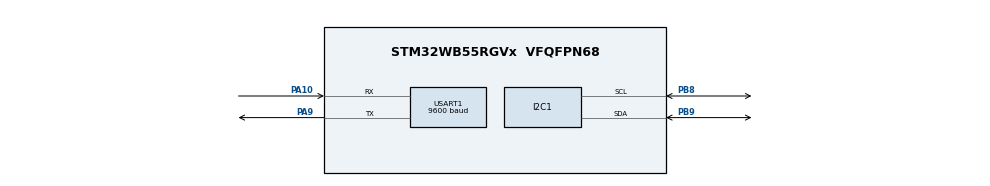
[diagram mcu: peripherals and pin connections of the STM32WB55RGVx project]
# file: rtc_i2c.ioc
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I2C1.Timing=0x00100D14
Mcu.Family=STM32WB
Mcu.Name=STM32WB55RGVx
Mcu.Package=VFQFPN68
NVIC.PriorityGroup=NVIC_PRIORITYGROUP_4
PA10.Mode=Asynchronous
PA10.Signal=USART1_RX
PA9.Mode=Asynchronous
PA9.Signal=USART1_TX
PB8.Mode=I2C
PB8.Signal=I2C1_SCL
PB9.Mode=I2C
PB9.Signal=I2C1_SDA
ProjectManager.HeapSize=0x200
ProjectManager.StackSize=0x400
ProjectManager.TargetToolchain=STM32CubeIDE
RCC.APB3Freq_Value=16000000
RCC.HSE_VALUE=8000000
RCC.HSI48_VALUE=48000000
RCC.HSI_VALUE=16000000
RCC.LSE_VALUE=32768
RCC.VCOOutputFreq_Value=32000000
USART1.BaudRate=9600
USART1.VirtualMode-Asynchronous=VM_ASYNC
VP_MEMORYMAP_VS_MEMORYMAP.Mode=CurAppReg
board=custom

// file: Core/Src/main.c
/* USER CODE BEGIN Header */
/**
  ******************************************************************************
  * @file           : main.c
  * @brief          : Main program body
  ******************************************************************************
  * @attention
  *
  * Copyright (c) 2025 STMicroelectronics.
  * All rights reserved.
  *
  * This software is licensed under terms that can be found in the LICENSE file
  * in the root directory of this software component.
  * If no LICENSE file comes with this software, it is provided AS-IS.
  *
  ******************************************************************************
  */
/* USER CODE END Header */
#include "main.h"
#include "RTC_MCP79410_I2C.h"

I2C_HandleTypeDef hi2c1;

UART_HandleTypeDef huart1;

/* USER CODE BEGIN PV */
char tempTimeArray[20];   // Format: HH MM SS
char tempDateArray[20];
/* USER CODE END PV */

void SystemClock_Config(void);
void PeriphCommonClock_Config(void);
static void MX_GPIO_Init(void);
static void MX_I2C1_Init(void);
static void MX_USART1_UART_Init(void);
void UART_Print(char *str);

/* USER CODE BEGIN 0 */
//void UART_Print(char *str)
//{
//    HAL_UART_Transmit(&huart1, (uint8_t *)str, strlen(str), HAL_MAX_DELAY);
//}
///* USER CODE END 0 */

int main(void)
{

  /* MCU Configuration--------------------------------------------------------*/

  /* Reset of all peripherals, Initializes the Flash interface and the Systick. */
  HAL_Init();

  /* Configure the system clock */
  SystemClock_Config();

  /* Configure the peripherals common clocks */
  PeriphCommonClock_Config();

  /* Initialize all configured peripherals */
  MX_GPIO_Init();
  MX_I2C1_Init();
  MX_USART1_UART_Init();
  InitRtc();

  /* Infinite loop */
  while (1)
  {

	   GetTimeToRtcHmsAscii(tempTimeArray);

	   HAL_UART_Transmit(&huart1, (uint8_t*) tempTimeArray, strlen( tempTimeArray), HAL_MAX_DELAY);
	   HAL_UART_Transmit(&huart1, (uint8_t*)"\r\n", 2, HAL_MAX_DELAY);

	   HAL_Delay(100);

	   GetDateToRtcHmsAscii(tempDateArray);

	   HAL_UART_Transmit(&huart1, (uint8_t*)tempDateArray, strlen(tempDateArray), HAL_MAX_DELAY);
	   HAL_UART_Transmit(&huart1, (uint8_t*)"\r\n", 2, HAL_MAX_DELAY);

	   HAL_Delay(100);

  }
}

void SystemClock_Config(void)
{
  RCC_OscInitTypeDef RCC_OscInitStruct = {0};
  RCC_ClkInitTypeDef RCC_ClkInitStruct = {0};

  /** Configure the main internal regulator output voltage
  */
  __HAL_PWR_VOLTAGESCALING_CONFIG(PWR_REGULATOR_VOLTAGE_SCALE1);

  /** Initializes the RCC Oscillators according to the specified parameters
  * in the RCC_OscInitTypeDef structure.
  */
  RCC_OscInitStruct.OscillatorType = RCC_OSCILLATORTYPE_HSI|RCC_OSCILLATORTYPE_MSI;
  RCC_OscInitStruct.HSIState = RCC_HSI_ON;
  RCC_OscInitStruct.MSIState = RCC_MSI_ON;
  RCC_OscInitStruct.HSICalibrationValue = RCC_HSICALIBRATION_DEFAULT;
  RCC_OscInitStruct.MSICalibrationValue = RCC_MSICALIBRATION_DEFAULT;
  RCC_OscInitStruct.MSIClockRange = RCC_MSIRANGE_6;
  RCC_OscInitStruct.PLL.PLLState = RCC_PLL_NONE;
  if (HAL_RCC_OscConfig(&RCC_OscInitStruct) != HAL_OK)
  {
    Error_Handler();
  }

  /** Configure the SYSCLKSource, HCLK, PCLK1 and PCLK2 clocks dividers
  */
  RCC_ClkInitStruct.ClockType = RCC_CLOCKTYPE_HCLK4|RCC_CLOCKTYPE_HCLK2
                              |RCC_CLOCKTYPE_HCLK|RCC_CLOCKTYPE_SYSCLK
                              |RCC_CLOCKTYPE_PCLK1|RCC_CLOCKTYPE_PCLK2;
  RCC_ClkInitStruct.SYSCLKSource = RCC_SYSCLKSOURCE_MSI;
  RCC_ClkInitStruct.AHBCLKDivider = RCC_SYSCLK_DIV1;
  RCC_ClkInitStruct.APB1CLKDivider = RCC_HCLK_DIV1;
  RCC_ClkInitStruct.APB2CLKDivider = RCC_HCLK_DIV1;
  RCC_ClkInitStruct.AHBCLK2Divider = RCC_SYSCLK_DIV1;
  RCC_ClkInitStruct.AHBCLK4Divider = RCC_SYSCLK_DIV1;

  if (HAL_RCC_ClockConfig(&RCC_ClkInitStruct, FLASH_LATENCY_0) != HAL_OK)
  {
    Error_Handler();
  }
}

void PeriphCommonClock_Config(void)
{
  RCC_PeriphCLKInitTypeDef PeriphClkInitStruct = {0};

  /** Initializes the peripherals clock
  */
  PeriphClkInitStruct.PeriphClockSelection = RCC_PERIPHCLK_SMPS;
  PeriphClkInitStruct.SmpsClockSelection = RCC_SMPSCLKSOURCE_HSI;
  PeriphClkInitStruct.SmpsDivSelection = RCC_SMPSCLKDIV_RANGE1;

  if (HAL_RCCEx_PeriphCLKConfig(&PeriphClkInitStruct) != HAL_OK)
  {
    Error_Handler();
  }
}

static void MX_I2C1_Init(void)
{

  hi2c1.Instance = I2C1;
  hi2c1.Init.Timing = 0x00100D14;
  hi2c1.Init.OwnAddress1 = 0;
  hi2c1.Init.AddressingMode = I2C_ADDRESSINGMODE_7BIT;
  hi2c1.Init.DualAddressMode = I2C_DUALADDRESS_DISABLE;
  hi2c1.Init.OwnAddress2 = 0;
  hi2c1.Init.OwnAddress2Masks = I2C_OA2_NOMASK;
  hi2c1.Init.GeneralCallMode = I2C_GENERALCALL_DISABLE;
  hi2c1.Init.NoStretchMode = I2C_NOSTRETCH_DISABLE;
  if (HAL_I2C_Init(&hi2c1) != HAL_OK)
  {
    Error_Handler();
  }

  /** Configure Analogue filter
  */
  if (HAL_I2CEx_ConfigAnalogFilter(&hi2c1, I2C_ANALOGFILTER_ENABLE) != HAL_OK)
  {
    Error_Handler();
  }

  /** Configure Digital filter
  */
  if (HAL_I2CEx_ConfigDigitalFilter(&hi2c1, 0) != HAL_OK)
  {
    Error_Handler();
  }

}

static void MX_USART1_UART_Init(void)
{

  huart1.Instance = USART1;
  huart1.Init.BaudRate = 9600;
  huart1.Init.WordLength = UART_WORDLENGTH_8B;
  huart1.Init.StopBits = UART_STOPBITS_1;
  huart1.Init.Parity = UART_PARITY_NONE;
  huart1.Init.Mode = UART_MODE_TX_RX;
  huart1.Init.HwFlowCtl = UART_HWCONTROL_NONE;
  huart1.Init.OverSampling = UART_OVERSAMPLING_16;
  huart1.Init.OneBitSampling = UART_ONE_BIT_SAMPLE_DISABLE;
  huart1.Init.ClockPrescaler = UART_PRESCALER_DIV1;
  huart1.AdvancedInit.AdvFeatureInit = UART_ADVFEATURE_NO_INIT;
  if (HAL_UART_Init(&huart1) != HAL_OK)
  {
    Error_Handler();
  }
  if (HAL_UARTEx_SetTxFifoThreshold(&huart1, UART_TXFIFO_THRESHOLD_1_8) != HAL_OK)
  {
    Error_Handler();
  }
  if (HAL_UARTEx_SetRxFifoThreshold(&huart1, UART_RXFIFO_THRESHOLD_1_8) != HAL_OK)
  {
    Error_Handler();
  }
  if (HAL_UARTEx_DisableFifoMode(&huart1) != HAL_OK)
  {
    Error_Handler();
  }

}

static void MX_GPIO_Init(void)
{

  /* GPIO Ports Clock Enable */
  __HAL_RCC_GPIOB_CLK_ENABLE();
  __HAL_RCC_GPIOA_CLK_ENABLE();

}

void Error_Handler(void)
{
  __disable_irq();
  while (1)
  {
  }
}
